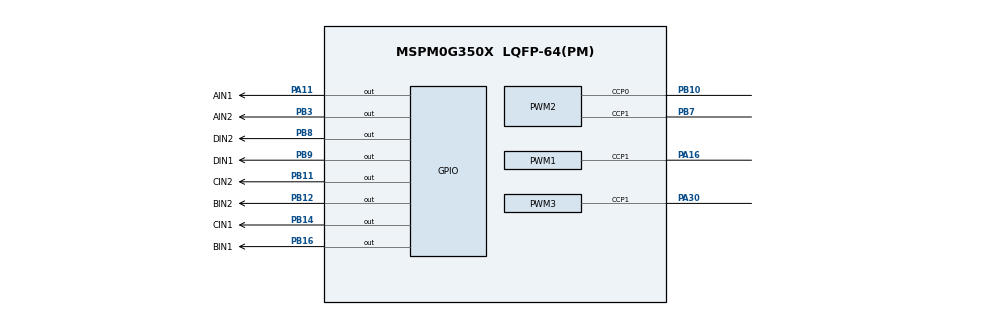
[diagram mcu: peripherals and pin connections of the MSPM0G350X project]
/**
 * @cliArgs --device "MSPM0G350X" --part "Default" --package "LQFP-64(PM)" --product "mspm0_sdk@2.10.00.04"
 * @versions {"tool":"1.27.0+4565"}
 */

/**
 * Import the modules used in this configuration.
 */
const GPIO   = scripting.addModule("/ti/driverlib/GPIO", {}, false);
const GPIO1  = GPIO.addInstance();
const GPIO2  = GPIO.addInstance();
const PWM    = scripting.addModule("/ti/driverlib/PWM", {}, false);
const PWM1   = PWM.addInstance();
const PWM2   = PWM.addInstance();
const PWM3   = PWM.addInstance();
const SYSCTL = scripting.addModule("/ti/driverlib/SYSCTL");
const TIMER  = scripting.addModule("/ti/driverlib/TIMER", {}, false);
const TIMER1 = TIMER.addInstance();

/**
 * Write custom configuration values to the imported modules.
 */
GPIO1.$name                          = "MOTOR";
GPIO1.associatedPins.create(8);
GPIO1.associatedPins[0].$name        = "AIN1";
GPIO1.associatedPins[0].assignedPort = "PORTA";
GPIO1.associatedPins[0].assignedPin  = "11";
GPIO1.associatedPins[0].pin.$assign  = "PA11";
GPIO1.associatedPins[1].$name        = "AIN2";
GPIO1.associatedPins[1].assignedPort = "PORTB";
GPIO1.associatedPins[1].assignedPin  = "3";
GPIO1.associatedPins[1].pin.$assign  = "PB3";
GPIO1.associatedPins[2].$name        = "BIN1";
GPIO1.associatedPins[2].assignedPort = "PORTB";
GPIO1.associatedPins[2].assignedPin  = "16";
GPIO1.associatedPins[2].pin.$assign  = "PB16";
GPIO1.associatedPins[3].$name        = "BIN2";
GPIO1.associatedPins[3].assignedPort = "PORTB";
GPIO1.associatedPins[3].assignedPin  = "12";
GPIO1.associatedPins[3].pin.$assign  = "PB12";
GPIO1.associatedPins[4].$name        = "CIN1";
GPIO1.associatedPins[4].assignedPort = "PORTB";
GPIO1.associatedPins[4].assignedPin  = "14";
GPIO1.associatedPins[4].pin.$assign  = "PB14";
GPIO1.associatedPins[5].$name        = "CIN2";
GPIO1.associatedPins[5].assignedPort = "PORTB";
GPIO1.associatedPins[5].assignedPin  = "11";
GPIO1.associatedPins[5].pin.$assign  = "PB11";
GPIO1.associatedPins[6].$name        = "DIN1";
GPIO1.associatedPins[6].assignedPort = "PORTB";
GPIO1.associatedPins[6].assignedPin  = "9";
GPIO1.associatedPins[6].pin.$assign  = "PB9";
GPIO1.associatedPins[7].$name        = "DIN2";
GPIO1.associatedPins[7].assignedPort = "PORTB";
GPIO1.associatedPins[7].assignedPin  = "8";
GPIO1.associatedPins[7].pin.$assign  = "PB8";

const Board = scripting.addModule("/ti/driverlib/Board", {}, false);

GPIO2.$name                          = "TRACK";
GPIO2.associatedPins.create(8);
GPIO2.associatedPins[0].$name        = "XIN1";
GPIO2.associatedPins[0].direction    = "INPUT";
GPIO2.associatedPins[0].assignedPort = "PORTB";
GPIO2.associatedPins[0].assignedPin  = "20";
GPIO2.associatedPins[1].$name        = "XIN2";
GPIO2.associatedPins[1].direction    = "INPUT";
GPIO2.associatedPins[1].assignedPort = "PORTB";
GPIO2.associatedPins[1].assignedPin  = "25";
GPIO2.associatedPins[2].$name        = "XIN3";
GPIO2.associatedPins[2].direction    = "INPUT";
GPIO2.associatedPins[2].assignedPort = "PORTA";
GPIO2.associatedPins[2].assignedPin  = "25";
GPIO2.associatedPins[3].$name        = "XIN4";
GPIO2.associatedPins[3].direction    = "INPUT";
GPIO2.associatedPins[3].assignedPort = "PORTA";
GPIO2.associatedPins[3].assignedPin  = "27";
GPIO2.associatedPins[4].$name        = "XIN5";
GPIO2.associatedPins[4].direction    = "INPUT";
GPIO2.associatedPins[4].assignedPort = "PORTB";
GPIO2.associatedPins[4].assignedPin  = "24";
GPIO2.associatedPins[5].$name        = "XIN6";
GPIO2.associatedPins[5].direction    = "INPUT";
GPIO2.associatedPins[5].assignedPort = "PORTA";
GPIO2.associatedPins[5].assignedPin  = "22";
GPIO2.associatedPins[6].$name        = "XIN7";
GPIO2.associatedPins[6].direction    = "INPUT";
GPIO2.associatedPins[6].assignedPort = "PORTA";
GPIO2.associatedPins[6].assignedPin  = "24";
GPIO2.associatedPins[7].$name        = "XIN8";
GPIO2.associatedPins[7].direction    = "INPUT";
GPIO2.associatedPins[7].assignedPort = "PORTA";
GPIO2.associatedPins[7].assignedPin  = "26";

PWM1.timerStartTimer                    = true;
PWM1.$name                              = "PWM_A";
PWM1.timerCount                         = 4000;
PWM1.ccIndex                            = [1];
PWM1.ccp1PinConfig.$name                = "ti_driverlib_gpio_GPIOPinGeneric1";
PWM1.ccp1PinConfig.direction            = scripting.forceWrite("OUTPUT");
PWM1.ccp1PinConfig.hideOutputInversion  = scripting.forceWrite(false);
PWM1.ccp1PinConfig.onlyInternalResistor = scripting.forceWrite(false);
PWM1.ccp1PinConfig.passedPeripheralType = scripting.forceWrite("Digital");
PWM1.peripheral.$assign                 = "TIMA1";
PWM1.peripheral.ccp1Pin.$assign         = "PA16";
PWM1.PWM_CHANNEL_1.$name                = "ti_driverlib_pwm_PWMTimerCC0";
PWM1.PWM_CHANNEL_1.invert               = true;

PWM2.$name                              = "PWM_B";
PWM2.timerCount                         = 4000;
PWM2.timerStartTimer                    = true;
PWM2.peripheral.ccp0Pin.$assign         = "PB10";
PWM2.peripheral.ccp1Pin.$assign         = "PB7";
PWM2.PWM_CHANNEL_0.$name                = "ti_driverlib_pwm_PWMTimerCC4";
PWM2.PWM_CHANNEL_0.invert               = true;
PWM2.PWM_CHANNEL_1.$name                = "ti_driverlib_pwm_PWMTimerCC5";
PWM2.PWM_CHANNEL_1.invert               = true;
PWM2.ccp0PinConfig.direction            = scripting.forceWrite("OUTPUT");
PWM2.ccp0PinConfig.hideOutputInversion  = scripting.forceWrite(false);
PWM2.ccp0PinConfig.onlyInternalResistor = scripting.forceWrite(false);
PWM2.ccp0PinConfig.passedPeripheralType = scripting.forceWrite("Digital");
PWM2.ccp0PinConfig.$name                = "ti_driverlib_gpio_GPIOPinGeneric4";
PWM2.ccp1PinConfig.direction            = scripting.forceWrite("OUTPUT");
PWM2.ccp1PinConfig.hideOutputInversion  = scripting.forceWrite(false);
PWM2.ccp1PinConfig.onlyInternalResistor = scripting.forceWrite(false);
PWM2.ccp1PinConfig.passedPeripheralType = scripting.forceWrite("Digital");
PWM2.ccp1PinConfig.$name                = "ti_driverlib_gpio_GPIOPinGeneric5";

PWM3.$name                              = "PWM_D";
PWM3.timerCount                         = 4000;
PWM3.timerStartTimer                    = true;
PWM3.ccIndex                            = [1];
PWM3.ccp1PinConfig.direction            = scripting.forceWrite("OUTPUT");
PWM3.ccp1PinConfig.hideOutputInversion  = scripting.forceWrite(false);
PWM3.ccp1PinConfig.onlyInternalResistor = scripting.forceWrite(false);
PWM3.ccp1PinConfig.passedPeripheralType = scripting.forceWrite("Digital");
PWM3.ccp1PinConfig.$name                = "ti_driverlib_gpio_GPIOPinGeneric7";
PWM3.peripheral.$assign                 = "TIMG8";
PWM3.peripheral.ccp1Pin.$assign         = "PA30";
PWM3.PWM_CHANNEL_1.$name                = "ti_driverlib_pwm_PWMTimerCC1";
PWM3.PWM_CHANNEL_1.invert               = true;

SYSCTL.forceDefaultClkConfig = true;
SYSCTL.clockTreeEn           = true;

TIMER1.$name              = "TIMER_SCH";
TIMER1.timerMode          = "PERIODIC";
TIMER1.timerStartTimer    = true;
TIMER1.interruptPriority  = "0";
TIMER1.timerClkPrescale   = 32;
TIMER1.timerPeriod        = "10ms";
TIMER1.peripheral.$assign = "TIMG0";

/**
 * Pinmux solution for unlocked pins/peripherals. This ensures that minor changes to the automatic solver in a future
 * version of the tool will not impact the pinmux you originally saw.  These lines can be completely deleted in order to
 * re-solve from scratch.
 */
Board.peripheral.$suggestSolution            = "DEBUGSS";
Board.peripheral.swclkPin.$suggestSolution   = "PA20";
Board.peripheral.swdioPin.$suggestSolution   = "PA19";
GPIO2.associatedPins[0].pin.$suggestSolution = "PB20";
GPIO2.associatedPins[1].pin.$suggestSolution = "PB25";
GPIO2.associatedPins[2].pin.$suggestSolution = "PA25";
GPIO2.associatedPins[3].pin.$suggestSolution = "PA27";
GPIO2.associatedPins[4].pin.$suggestSolution = "PB24";
GPIO2.associatedPins[5].pin.$suggestSolution = "PA22";
GPIO2.associatedPins[6].pin.$suggestSolution = "PA24";
GPIO2.associatedPins[7].pin.$suggestSolution = "PA26";
PWM2.peripheral.$suggestSolution             = "TIMG6";
